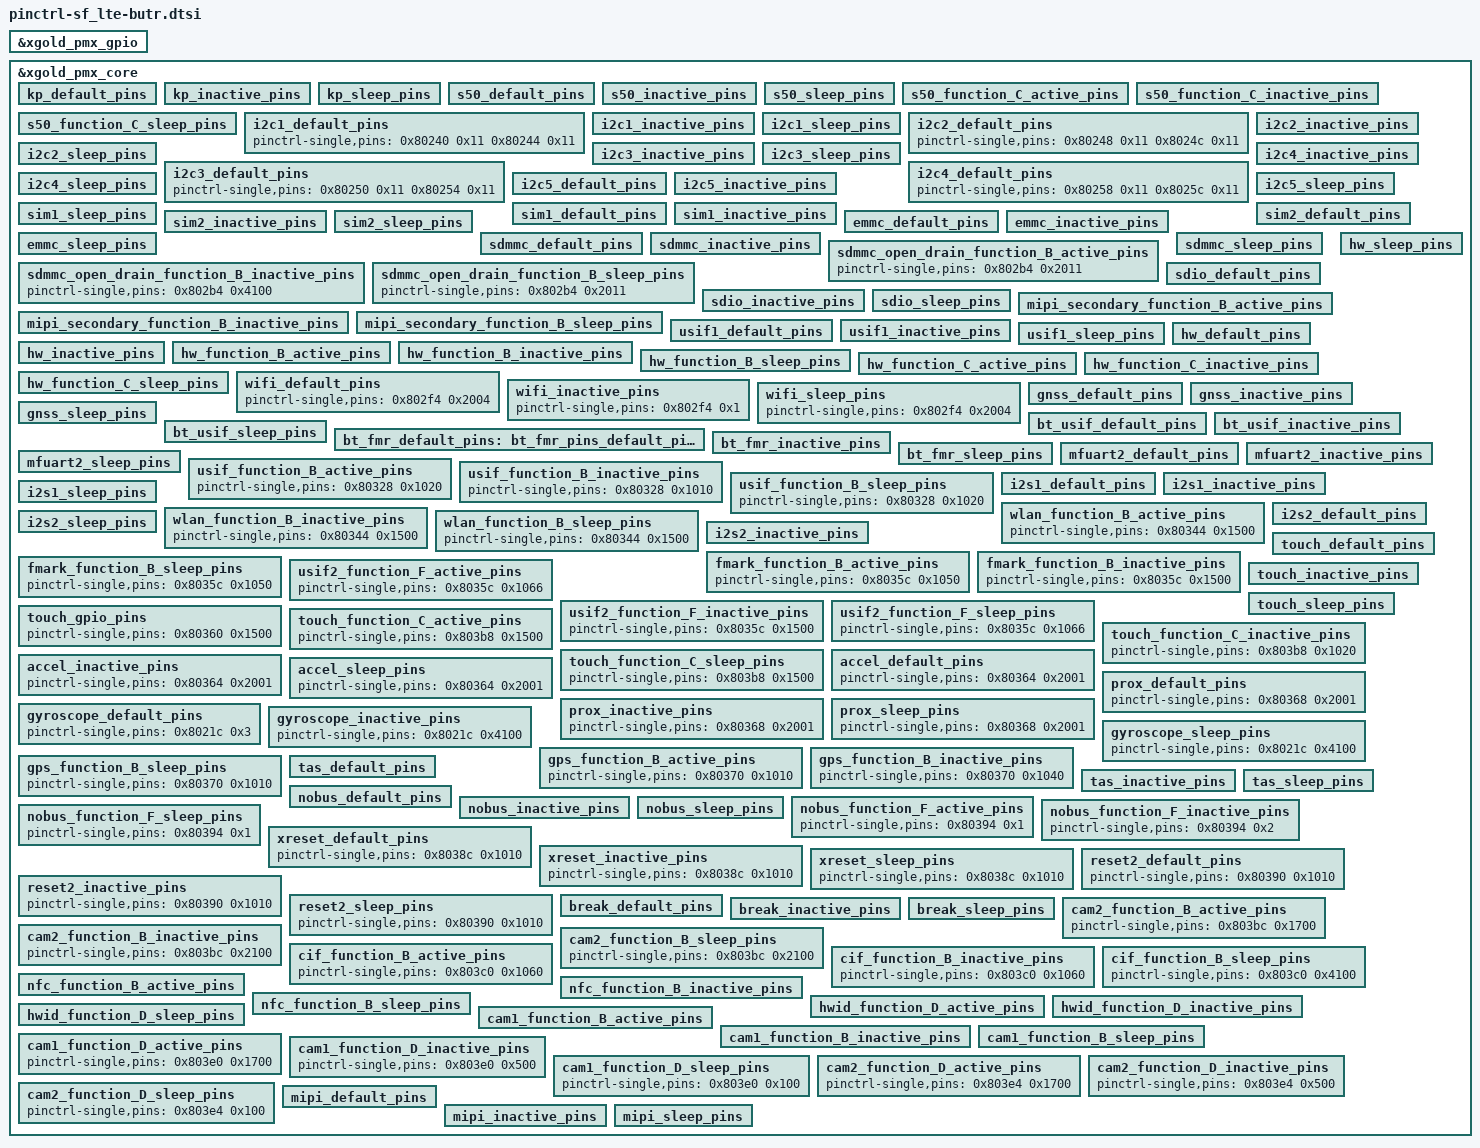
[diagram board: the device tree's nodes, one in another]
&xgold_pmx_gpio {
		intel,gpio-to-irq-num = < 16 >;
		intel,gpio-to-irq = <
			12 117  /* EXT_INT0 */
			67 118  /* EXT_INT1 */
			71 119  /* EXT_INT2 */
			14 120  /* EXT_INT3 */
			11 121  /* EXT_INT4 */
			27 122  /* EXT_INT5 */
			47 123  /* EXT_INT6 */
			45 124  /* EXT_INT7 */
			49 125  /* EXT_INT8 */
			70 126  /* EXT_INT9 */
			16 127  /* EXT_INT10 */
			17 128  /* EXT_INT11 */
			18 129  /* EXT_INT12 */
			19 130  /* EXT_INT13 */
			52 131  /* EXT_INT14 */
			56 132 >; /* EXT_INT15 */
};
&xgold_pmx_core {
	/* sparse GPIO range could be supported */
		/*first pin / nb pins / value */
	pinctrl-single,gpio-range =
		<&range 0 14 0x100>,
		<&range 15 1 0x1700>,   /* dif_reset */
		<&range 16 55 0x100>,
		<&range 71 1 0x1700>,   /* gnss_poweron */
		<&range 72 5 0x100>,
		<&range 77 1 0x1500>,   /* bt_fmr_enable*/
		<&range 78 10 0x100>,
		<&range 88 1 0x01700>,  /* touch_irq */
		<&range 89 21 0x100>,
		<&range 110 1 0x1500>,  /* touch_reset */
		<&range 111 1 0x01500>,	/* cam2_pd */
		<&range 112 6 0x100>,
		<&range 118 1 0x01500>,	/* cam1_pd */
		<&range 119 1 0x100>,
		<&range 120 1 0x01500>,	/* cam1_rst */
		<&range 121 1 0x01500>,	/* cam2_rst */
		<&range 122 20 0x100>;

	pinctrl-names = "default", "sleep", "deactivate"; /*"activate", "sleep", "deactivate" */
	/* map here static pins (do not need any dynamic config) */
	pinctrl-0 = <>;
	pinctrl-1 = <>;
	pinctrl-2 = <>;


	kp_default_pins:kp_default_pins {
		pinctrl-single,pins = <
			0x80200 0x2001	/* kp_in0 */
			0x80204 0x2001	/* kp_in1 */
			0x80220 0x10	/* kp_out0 */
			0x80228 0x10	/* kp_out2 */
		>;
	};
	kp_inactive_pins:kp_inactive_pins {
		pinctrl-single,pins = <
			0x80200 0x2001	/* kp_in0 */
			0x80204 0x2001	/* kp_in1 */
			0x80220 0x10	/* kp_out0 */
			0x80228 0x10	/* kp_out2 */
		>;
	};
	kp_sleep_pins:kp_sleep_pins {
		pinctrl-single,pins = <
			0x80200 0x2001	/* kp_in0 */
			0x80204 0x2001	/* kp_in1 */
			0x80220 0x10	/* kp_out0 */
			0x80228 0x10	/* kp_out2 */
		>;
	};
	s50_default_pins:s50_default_pins {
		pinctrl-single,pins = <
			0x803b4 0x1020	/* s50_tpiu_traceclk */
			0x803b8 0x1020	/* s50_tpiu_tracectl */
		>;
	};
	s50_inactive_pins:s50_inactive_pins {
		pinctrl-single,pins = <
			0x803b4 0x1020	/* s50_tpiu_traceclk */
			0x803b8 0x1020	/* s50_tpiu_tracectl */
		>;
	};
	s50_sleep_pins:s50_sleep_pins {
		pinctrl-single,pins = <
			0x803b4 0x1020	/* s50_tpiu_traceclk */
			0x803b8 0x1020	/* s50_tpiu_tracectl */
		>;
	};
	s50_function_C_active_pins:s50_function_C_active_pins {
		pinctrl-single,pins = <
			0x80200 0x1060	/* s50_tpiu_tracedata0 */
			0x80204 0x1060	/* s50_tpiu_tracedata1 */
			0x80220 0x1060	/* s50_tpiu_tracedata8 */
		>;
	};
	s50_function_C_inactive_pins:s50_function_C_inactive_pins {
		pinctrl-single,pins = <
			0x80200 0x2001	/* s50_tpiu_tracedata0 */
			0x80204 0x2001	/* s50_tpiu_tracedata1 */
			0x80220 0x10	/* s50_tpiu_tracedata8 */
		>;
	};
	s50_function_C_sleep_pins:s50_function_C_sleep_pins {
		pinctrl-single,pins = <
			0x80200 0x1060	/* s50_tpiu_tracedata0 */
			0x80204 0x1060	/* s50_tpiu_tracedata1 */
			0x80220 0x1060	/* s50_tpiu_tracedata8 */
		>;
	};
	i2c1_default_pins:i2c1_default_pins {
		pinctrl-single,pins = <
			0x80240 0x11	/* i2c1_scl */
			0x80244 0x11	/* i2c1_sda */
		>;
	};
	i2c1_inactive_pins:i2c1_inactive_pins {
		pinctrl-single,pins = <
			0x80240 0x2100	/* i2c1_scl */
			0x80244 0x2100	/* i2c1_sda */
		>;
	};
	i2c1_sleep_pins:i2c1_sleep_pins {
		pinctrl-single,pins = <
			0x80240 0x100	/* i2c1_scl */
			0x80244 0x100	/* i2c1_sda */
		>;
	};
	i2c2_default_pins:i2c2_default_pins {
		pinctrl-single,pins = <
			0x80248 0x11	/* i2c2_scl */
			0x8024c 0x11	/* i2c2_sda */
		>;
	};
	i2c2_inactive_pins:i2c2_inactive_pins {
		pinctrl-single,pins = <
			0x80248 0x2100	/* i2c2_scl */
			0x8024c 0x2100	/* i2c2_sda */
		>;
	};
	i2c2_sleep_pins:i2c2_sleep_pins {
		pinctrl-single,pins = <
			0x80248 0x100	/* i2c2_scl */
			0x8024c 0x100	/* i2c2_sda */
		>;
	};
	i2c3_default_pins:i2c3_default_pins {
		pinctrl-single,pins = <
			0x80250 0x11	/* i2c3_scl */
			0x80254 0x11	/* i2c3_sda */
		>;
	};
	i2c3_inactive_pins:i2c3_inactive_pins {
		pinctrl-single,pins = <
			0x80250 0x2100	/* i2c3_scl */
			0x80254 0x2100	/* i2c3_sda */
		>;
	};
	i2c3_sleep_pins:i2c3_sleep_pins {
		pinctrl-single,pins = <
			0x80250 0x100	/* i2c3_scl */
			0x80254 0x100	/* i2c3_sda */
		>;
	};
	i2c4_default_pins:i2c4_default_pins {
		pinctrl-single,pins = <
			0x80258 0x11	/* i2c4_scl */
			0x8025c 0x11	/* i2c4_sda */
		>;
	};
	i2c4_inactive_pins:i2c4_inactive_pins {
		pinctrl-single,pins = <
			0x80258 0x2100	/* i2c4_scl */
			0x8025c 0x2100	/* i2c4_sda */
		>;
	};
	i2c4_sleep_pins:i2c4_sleep_pins {
		pinctrl-single,pins = <
			0x80258 0x100	/* i2c4_scl */
			0x8025c 0x100	/* i2c4_sda */
		>;
	};
	i2c5_default_pins:i2c5_default_pins {
		pinctrl-single,pins = <
			0x80260 0x2011	/* i2c5_scl */
			0x80264 0x2011	/* i2c5_sda */
		>;
	};
	i2c5_inactive_pins:i2c5_inactive_pins {
		pinctrl-single,pins = <
			0x80260 0x2100	/* i2c5_scl */
			0x80264 0x2100	/* i2c5_sda */
		>;
	};
	i2c5_sleep_pins:i2c5_sleep_pins {
		pinctrl-single,pins = <
			0x80260 0x100	/* i2c5_scl */
			0x80264 0x100	/* i2c5_sda */
		>;
	};
	sim1_default_pins:sim1_default_pins {
		pinctrl-single,pins = <
			0x80268 0x11	/* sim1_io */
			0x8026c 0x1010	/* sim1_rst */
			0x80270 0x1010	/* sim1_clk */
			0x80274 0x1	/* sim1_sw */
		>;
	};
	sim1_inactive_pins:sim1_inactive_pins {
		pinctrl-single,pins = <
			0x80268 0x11	/* sim1_io */
			0x8026c 0x10	/* sim1_rst */
			0x80270 0x10	/* sim1_clk */
			0x80274 0x100	/* sim1_sw */
		>;
	};
	sim1_sleep_pins:sim1_sleep_pins {
		pinctrl-single,pins = <
			0x80268 0x11	/* sim1_io */
			0x8026c 0x1010	/* sim1_rst */
			0x80270 0x1010	/* sim1_clk */
			0x80274 0x1	/* sim1_sw */
		>;
	};
	sim2_default_pins:sim2_default_pins {
		pinctrl-single,pins = <
			0x80278 0x11	/* sim2_io */
			0x8027c 0x1010	/* sim2_clk */
			0x80280 0x1010	/* sim2_rst */
			0x80284 0x1	/* sim2_det */
		>;
	};
	sim2_inactive_pins:sim2_inactive_pins {
		pinctrl-single,pins = <
			0x80278 0x11	/* sim2_io */
			0x8027c 0x10	/* sim2_clk */
			0x80280 0x10	/* sim2_rst */
			0x80284 0x100	/* sim2_det */
		>;
	};
	sim2_sleep_pins:sim2_sleep_pins {
		pinctrl-single,pins = <
			0x80278 0x11	/* sim2_io */
			0x8027c 0x1010	/* sim2_clk */
			0x80280 0x1010	/* sim2_rst */
			0x80284 0x1	/* sim2_det */
		>;
	};
	emmc_default_pins:emmc_default_pins {
		pinctrl-single,pins = <
			0x80288 0x31011	/* emmc_clk */
			0x8028c 0x33011	/* emmc_cmd */
			0x80290 0x33011	/* emmc_dat0 */
			0x80294 0x33011	/* emmc_dat1 */
			0x80298 0x33011	/* emmc_dat2 */
			0x8029c 0x33011	/* emmc_dat3 */
			0x802a0 0x33011	/* emmc_dat4 */
			0x802a4 0x33011	/* emmc_dat5 */
			0x802a8 0x33011	/* emmc_dat6 */
			0x802ac 0x33011	/* emmc_dat7 */
			0x802b0 0x11010	/* emmc_reset */
		>;
	};
	emmc_inactive_pins:emmc_inactive_pins {
		pinctrl-single,pins = <
			0x80288 0x2100	/* emmc_clk */
			0x8028c 0x2100	/* emmc_cmd */
			0x80290 0x2100	/* emmc_dat0 */
			0x80294 0x2100	/* emmc_dat1 */
			0x80298 0x2100	/* emmc_dat2 */
			0x8029c 0x2100	/* emmc_dat3 */
			0x802a0 0x2100	/* emmc_dat4 */
			0x802a4 0x2100	/* emmc_dat5 */
			0x802a8 0x2100	/* emmc_dat6 */
			0x802ac 0x2100	/* emmc_dat7 */
			0x802b0 0x2100	/* emmc_reset */
		>;
	};
	emmc_sleep_pins:emmc_sleep_pins {
		pinctrl-single,pins = <
			0x80288 0x1010	/* emmc_clk */
			0x8028c 0x3011	/* emmc_cmd */
			0x80290 0x3011	/* emmc_dat0 */
			0x80294 0x3011	/* emmc_dat1 */
			0x80298 0x3011	/* emmc_dat2 */
			0x8029c 0x3011	/* emmc_dat3 */
			0x802a0 0x3011	/* emmc_dat4 */
			0x802a4 0x3011	/* emmc_dat5 */
			0x802a8 0x3011	/* emmc_dat6 */
			0x802ac 0x3011	/* emmc_dat7 */
			0x802b0 0x1010	/* emmc_reset */
		>;
	};
	sdmmc_default_pins:sdmmc_default_pins {
		pinctrl-single,pins = <
			0x802b4 0x3011	/* sdmmc_cmd */
			0x802b8 0x3011	/* sdmmc_clk */
			0x802bc 0x3011	/* sdmmc_dat0 */
			0x802c0 0x3011	/* sdmmc_dat1 */
			0x802c4 0x3011	/* sdmmc_dat2 */
			0x802c8 0x1011	/* sdmmc_dat3 */
			0x802cc 0x1100	/* sdmmc_card_detect */
		>;
	};
	sdmmc_inactive_pins:sdmmc_inactive_pins {
		pinctrl-single,pins = <
			0x802b4 0x4100	/* sdmmc_cmd */
			0x802b8 0x4100	/* sdmmc_clk */
			0x802bc 0x4100	/* sdmmc_dat0 */
			0x802c0 0x4100	/* sdmmc_dat1 */
			0x802c4 0x4100	/* sdmmc_dat2 */
			0x802c8 0x4100	/* sdmmc_dat3 */
			0x802cc 0x1	/* sdmmc_card_detect */
		>;
	};
	sdmmc_sleep_pins:sdmmc_sleep_pins {
		pinctrl-single,pins = <
			0x802b4 0x3011	/* sdmmc_cmd */
			0x802b8 0x3011	/* sdmmc_clk */
			0x802bc 0x3011	/* sdmmc_dat0 */
			0x802c0 0x3011	/* sdmmc_dat1 */
			0x802c4 0x3011	/* sdmmc_dat2 */
			0x802c8 0x1011	/* sdmmc_dat3 */
			0x802cc 0x1	/* sdmmc_card_detect */
		>;
	};
	sdmmc_open_drain_function_B_active_pins:sdmmc_open_drain_function_B_active_pins {
		pinctrl-single,pins = <
			0x802b4 0x2011	/* sdmmc_cmd_open_drain */
		>;
	};
	sdmmc_open_drain_function_B_inactive_pins:sdmmc_open_drain_function_B_inactive_pins {
		pinctrl-single,pins = <
			0x802b4 0x4100	/* sdmmc_cmd_open_drain */
		>;
	};
	sdmmc_open_drain_function_B_sleep_pins:sdmmc_open_drain_function_B_sleep_pins {
		pinctrl-single,pins = <
			0x802b4 0x2011	/* sdmmc_cmd_open_drain */
		>;
	};

	sdio_default_pins:sdio_default_pins {
		pinctrl-single,pins = <
			0x802d0 0x33011	/* sdio_cmd */
			0x802d4 0x33011	/* sdio_clk */
			0x802d8 0x33011	/* sdio_dat0 */
			0x802dc 0x33011	/* sdio_dat1 */
			0x802e0 0x33011	/* sdio_dat2 */
			0x802e4 0x33011	/* sdio_dat3 */
			0x802e8 0x2006  /* sdio_card_reset */
			0x80344 0x1700	/* i2s1_wa1 */
		>;
	};
	sdio_inactive_pins:sdio_inactive_pins {
		pinctrl-single,pins = <
			0x802d0 0x4100	/* sdio_cmd */
			0x802d4 0x4100	/* sdio_clk */
			0x802d8 0x4100	/* sdio_dat0 */
			0x802dc 0x4100	/* sdio_dat1 */
			0x802e0 0x4100	/* sdio_dat2 */
			0x802e4 0x4100	/* sdio_dat3 */
			0x802e8 0x2100	/* sdio_card_reset */
			0x80344 0x1500	/* i2s1_wa1 */
		>;
	};
	sdio_sleep_pins:sdio_sleep_pins {
		pinctrl-single,pins = <
			0x802d0 0x3011	/* sdio_cmd */
			0x802d4 0x3011	/* sdio_clk */
			0x802d8 0x3011	/* sdio_dat0 */
			0x802dc 0x3011	/* sdio_dat1 */
			0x802e0 0x3011	/* sdio_dat2 */
			0x802e4 0x3011	/* sdio_dat3 */
			0x802e8 0x2006	/* sdio_card_reset */
			0x80344 0x1500	/* i2s1_wa1 */
		>;
	};

	mipi_secondary_function_B_active_pins:mipi_secondary_function_B_active_pins {
		pinctrl-single,pins = <
			0x802b8 0x1030	/* mipi_trace_clk_secondary */
			0x802bc 0x1030	/* mipi_trace_data0_secondary */
			0x802c0 0x1030	/* mipi_trace_data1_secondary */
			0x802c4 0x1030	/* mipi_trace_data2_secondary */
			0x802c8 0x1030	/* mipi_trace_data3_secondary */
		>;
	};
	mipi_secondary_function_B_inactive_pins:mipi_secondary_function_B_inactive_pins {
		pinctrl-single,pins = <
			0x802b8 0x4100	/* mipi_trace_clk_secondary */
			0x802bc 0x4100	/* mipi_trace_data0_secondary */
			0x802c0 0x4100	/* mipi_trace_data1_secondary */
			0x802c4 0x4100	/* mipi_trace_data2_secondary */
			0x802c8 0x4100	/* mipi_trace_data3_secondary */
		>;
	};
	mipi_secondary_function_B_sleep_pins:mipi_secondary_function_B_sleep_pins {
		pinctrl-single,pins = <
			0x802b8 0x1030	/* mipi_trace_clk_secondary */
			0x802bc 0x1030	/* mipi_trace_data0_secondary */
			0x802c0 0x1030	/* mipi_trace_data1_secondary */
			0x802c4 0x1030	/* mipi_trace_data2_secondary */
			0x802c8 0x1030	/* mipi_trace_data3_secondary */
		>;
	};
	usif1_default_pins:usif1_default_pins {
		pinctrl-single,pins = <
			0x802ec 0x1010	/* usif1_txd_mtsr */
			0x802f0 0x2001	/* usif1_rxd_mrst */
			0x802f8 0x1010	/* usif1_rts_n */
			0x802fc 0x2001	/* usif1_cts_n */
		>;
	};
	usif1_inactive_pins:usif1_inactive_pins {
		pinctrl-single,pins = <
			0x802ec 0x1010	/* usif1_txd_mtsr */
			0x802f0 0x2001	/* usif1_rxd_mrst */
			0x802f8 0x1010	/* usif1_rts_n */
			0x802fc 0x2001	/* usif1_cts_n */
		>;
	};
	usif1_sleep_pins:usif1_sleep_pins {
		pinctrl-single,pins = <
			0x802ec 0x1010	/* usif1_txd_mtsr */
			0x802f0 0x2001	/* usif1_rxd_mrst */
			0x802f8 0x1010	/* usif1_rts_n */
			0x802fc 0x2001	/* usif1_cts_n */
		>;
	};
	hw_default_pins:hw_default_pins {
		pinctrl-single,pins = <
			0x803bc 0x1010	/* hw_mon18 */
			0x803c0 0x1010	/* hw_mon19 */
			0x803d0 0x1010	/* hw_mon23 */
			0x803d4 0x1010	/* hw_mon24 */
			0x803d8 0x1010	/* hw_mon25 */
			0x803e0 0x1010	/* hw_mon27 */
			0x803e4 0x1010	/* hw_mon28 */
			0x803e8 0x1010	/* hw_mon29 */
		>;
	};
	hw_inactive_pins:hw_inactive_pins {
		pinctrl-single,pins = <
			0x803bc 0x1500	/* hw_mon18 */
			0x803c0 0x1060	/* hw_mon19 */
			0x803d0 0x1500	/* hw_mon23 */
			0x803d4 0x1500	/* hw_mon24 */
			0x803d8 0x1700	/* hw_mon25 */
			0x803e0 0x500	/* hw_mon27 */
			0x803e4 0x500	/* hw_mon28 */
			0x803e8 0x1500	/* hw_mon29 */
		>;
	};
	hw_sleep_pins:hw_sleep_pins {
		pinctrl-single,pins = <
			0x803bc 0x1010	/* hw_mon18 */
			0x803c0 0x1010	/* hw_mon19 */
			0x803d0 0x1010	/* hw_mon23 */
			0x803d4 0x1010	/* hw_mon24 */
			0x803d8 0x1410	/* hw_mon25 */
			0x803e0 0x1410	/* hw_mon27 */
			0x803e4 0x1410	/* hw_mon28 */
			0x803e8 0x1410	/* hw_mon29 */
		>;
	};
	hw_function_B_active_pins:hw_function_B_active_pins {
		pinctrl-single,pins = <
			0x802ec 0x1020	/* hw_mon12 */
			0x802f0 0x1020	/* hw_mon13 */
			0x802f4 0x1020	/* hw_mon14 */
			0x802f8 0x1020	/* hw_mon15 */
			0x80310 0x1020	/* hw_mon3 */
			0x80314 0x1020	/* hw_mon4 */
			0x80320 0x1020	/* hw_mon5 */
			0x80324 0x1020	/* hw_mon6 */
			0x803b4 0x1010	/* hw_mon16 */
			0x803b8 0x1010	/* hw_mon17 */
			0x803f8 0x1030	/* hw_mon8 */
			0x803fc 0x1030	/* hw_mon9 */
			0x80400 0x1030	/* hw_mon10 */
			0x80404 0x1030	/* hw_mon11 */
			0x80418 0x1030	/* hw_mon7 */
		>;
	};
	hw_function_B_inactive_pins:hw_function_B_inactive_pins {
		pinctrl-single,pins = <
			0x802ec 0x1010	/* hw_mon12 */
			0x802f0 0x2001	/* hw_mon13 */
			0x802f4 0x1	/* hw_mon14 */
			0x802f8 0x1010	/* hw_mon15 */
			0x80310 0x1010	/* hw_mon3 */
			0x80314 0x2001	/* hw_mon4 */
			0x80320 0x1010	/* hw_mon5 */
			0x80324 0x2001	/* hw_mon6 */
			0x803b4 0x1020	/* hw_mon16 */
			0x803b8 0x1020	/* hw_mon17 */
			0x803f8 0x1010	/* hw_mon8 */
			0x803fc 0x1010	/* hw_mon9 */
			0x80400 0x1010	/* hw_mon10 */
			0x80404 0x1010	/* hw_mon11 */
			0x80418 0x1010	/* hw_mon7 */
		>;
	};
	hw_function_B_sleep_pins:hw_function_B_sleep_pins {
		pinctrl-single,pins = <
			0x802ec 0x1020	/* hw_mon12 */
			0x802f0 0x1020	/* hw_mon13 */
			0x802f4 0x1020	/* hw_mon14 */
			0x802f8 0x1020	/* hw_mon15 */
			0x80310 0x1020	/* hw_mon3 */
			0x80314 0x1020	/* hw_mon4 */
			0x80320 0x1020	/* hw_mon5 */
			0x80324 0x1020	/* hw_mon6 */
			0x803b4 0x1010	/* hw_mon16 */
			0x803b8 0x1010	/* hw_mon17 */
			0x803f8 0x1030	/* hw_mon8 */
			0x803fc 0x1030	/* hw_mon9 */
			0x80400 0x1030	/* hw_mon10 */
			0x80404 0x1030	/* hw_mon11 */
			0x80418 0x1030	/* hw_mon7 */
		>;
	};
	hw_function_C_active_pins:hw_function_C_active_pins {
		pinctrl-single,pins = <
			0x803ac 0x1010	/* hw_mon2 */
			0x803b0 0x1010	/* hw_mon2 */
		>;
	};
	hw_function_C_inactive_pins:hw_function_C_inactive_pins {
		pinctrl-single,pins = <
			0x803ac 0x1020	/* hw_mon2 */
			0x803b0 0x1500	/* hw_mon2 */
		>;
	};
	hw_function_C_sleep_pins:hw_function_C_sleep_pins {
		pinctrl-single,pins = <
			0x803ac 0x1010	/* hw_mon2 */
			0x803b0 0x1010	/* hw_mon2 */
		>;
	};
	wifi_default_pins:wifi_default_pins {
		pinctrl-single,pins = <
			0x802f4 0x2004	/* wifi_audio_irq */
		>;
	};
	wifi_inactive_pins:wifi_inactive_pins {
		pinctrl-single,pins = <
			0x802f4 0x1	/* wifi_audio_irq */
		>;
	};
	wifi_sleep_pins:wifi_sleep_pins {
		pinctrl-single,pins = <
			0x802f4 0x2004	/* wifi_audio_irq */
		>;
	};
	gnss_default_pins:gnss_default_pins {
		pinctrl-single,pins = <
			0x80300 0x1010	/* gnss_uart_txd */
			0x80304 0x2001	/* gnss_uart_rxd */
			0x80308 0x1010	/* gnss_uart_rts */
			0x8030c 0x2001	/* gnss_uart_cts */
			0x8031c 0x1500	/* gnss_poweron */
			0x8036c 0x1020	/* gnss_ext_frm_sync */
			0x80370 0x1040	/* gnss_ext_duty_cycle */
		>;
	};
	gnss_inactive_pins:gnss_inactive_pins {
		pinctrl-single,pins = <
			0x80300 0x1010	/* gnss_uart_txd */
			0x80304 0x2001	/* gnss_uart_rxd */
			0x80308 0x1010	/* gnss_uart_rts */
			0x8030c 0x2001	/* gnss_uart_cts */
			0x8036c 0x1020	/* gnss_ext_frm_sync */
			0x80370 0x1040	/* gnss_ext_duty_cycle */
		>;
	};
	gnss_sleep_pins:gnss_sleep_pins {
		pinctrl-single,pins = <
			0x80300 0x1010	/* gnss_uart_txd */
			0x80304 0x2001	/* gnss_uart_rxd */
			0x80308 0x1010	/* gnss_uart_rts */
			0x8030c 0x2001	/* gnss_uart_cts */
			0x8036c 0x1020	/* gnss_ext_frm_sync */
			0x80370 0x1040	/* gnss_ext_duty_cycle */
		>;
	};

	bt_usif_default_pins:bt_usif_default_pins {
		pinctrl-single,pins = <
			0x80310 0x1010	/* bt_uart_txd */
			0x80314 0x2001	/* bt_uart_rxd */
			0x80320 0x1010	/* bt_uart_rts */
			0x80324 0x2001	/* bt_uart_cts */
		>;
	};
	bt_usif_inactive_pins:bt_usif_inactive_pins {
		pinctrl-single,pins = <
			0x80310 0x1010	/* bt_uart_txd */
			0x80314 0x2001	/* bt_uart_rxd */
			0x80320 0x1010	/* bt_uart_rts */
			0x80324 0x2001	/* bt_uart_cts */
		>;
	};
	bt_usif_sleep_pins:bt_usif_sleep_pins {
		pinctrl-single,pins = <
			0x80310 0x1010	/* bt_uart_txd */
			0x80314 0x2001	/* bt_uart_rxd */
			0x80320 0x1010	/* bt_uart_rts */
			0x80324 0x2001	/* bt_uart_cts */
		>;
	};

	bt_fmr_default_pins:bt_fmr_pins_default_pins {
		pinctrl-single,pins = <
			0x80334 0x1500	/* bt_fm_en */
			0x80318 0x2003	/* bt_wakeup_host */
		>;
	};

	bt_fmr_inactive_pins:bt_fmr_inactive_pins {
		pinctrl-single,pins = <
			0x80334 0x1500	/* bt_fm_en */
			0x80318 0x1010	/* bt_wakeup_host */
		>;
	};

	bt_fmr_sleep_pins:bt_fmr_sleep_pins {
		pinctrl-single,pins = <
			0x80334 0x1500	/* bt_fm_en */
			0x80318 0x2003	/* bt_wakeup_host */
		>;
	};

	mfuart2_default_pins:mfuart2_default_pins {
		pinctrl-single,pins = <
			0x80328 0x1010	/* mfuart2_txd */
			0x8032c 0x2001	/* mfuart2_rxd */
		>;
	};
	mfuart2_inactive_pins:mfuart2_inactive_pins {
		pinctrl-single,pins = <
			0x80328 0x1010	/* mfuart2_txd */
			0x8032c 0x2001	/* mfuart2_rxd */
		>;
	};
	mfuart2_sleep_pins:mfuart2_sleep_pins {
		pinctrl-single,pins = <
			0x80328 0x1010	/* mfuart2_txd */
			0x8032c 0x2001	/* mfuart2_rxd */
		>;
	};
	usif_function_B_active_pins:usif_function_B_active_pins {
		pinctrl-single,pins = <
			0x80328 0x1020	/* usif_lte_txd */
		>;
	};
	usif_function_B_inactive_pins:usif_function_B_inactive_pins {
		pinctrl-single,pins = <
			0x80328 0x1010	/* usif_lte_txd */
		>;
	};
	usif_function_B_sleep_pins:usif_function_B_sleep_pins {
		pinctrl-single,pins = <
			0x80328 0x1020	/* usif_lte_txd */
		>;
	};
	i2s1_default_pins:i2s1_default_pins {
		pinctrl-single,pins = <
			0x80330 0x1010	/* i2s1_clk0 */
			0x80338 0x4001	/* i2s1_rx */
			0x8033c 0x1010	/* i2s1_tx */
			0x80340 0x1010	/* i2s1_wa0 */
		>;
	};
	i2s1_inactive_pins:i2s1_inactive_pins {
		pinctrl-single,pins = <
			0x80330 0x1500	/* i2s1_clk0 */
			0x80338 0x2100	/* i2s1_rx */
			0x8033c 0x1500	/* i2s1_tx */
			0x80340 0x1500	/* i2s1_wa0 */
		>;
	};
	i2s1_sleep_pins:i2s1_sleep_pins {
		pinctrl-single,pins = <
			0x80330 0x1500	/* i2s1_clk0 */
			0x80338 0x4100	/* i2s1_rx */
			0x8033c 0x1500	/* i2s1_tx */
			0x80340 0x1500	/* i2s1_wa0 */
		>;
	};
	wlan_function_B_active_pins:wlan_function_B_active_pins {
		pinctrl-single,pins = <
			0x80344 0x1500	/* wlan_en */
		>;
	};
	wlan_function_B_inactive_pins:wlan_function_B_inactive_pins {
		pinctrl-single,pins = <
			0x80344 0x1500	/* wlan_en */
		>;
	};
	wlan_function_B_sleep_pins:wlan_function_B_sleep_pins {
		pinctrl-single,pins = <
			0x80344 0x1500	/* wlan_en */
		>;
	};
	i2s2_default_pins:i2s2_default_pins {
		pinctrl-single,pins = <
			0x80348 0x1010	/* i2s2_clk0 */
			0x8034c 0x1010	/* i2s2_clk1 */
			0x80350 0x1	/* i2s2_rx */
			0x80354 0x1010	/* i2s2_tx */
			0x80358 0x1010	/* i2s2_wa0 */
			0x8035c 0x1010	/* i2s2_wa1 */
		>;
	};
	i2s2_inactive_pins:i2s2_inactive_pins {
		pinctrl-single,pins = <
			0x80348 0x1500	/* i2s2_clk0 */
			0x8034c 0x1500	/* i2s2_clk1 */
			0x80350 0x2100	/* i2s2_rx */
			0x80354 0x1500	/* i2s2_tx */
			0x80358 0x1500	/* i2s2_wa0 */
			0x8035c 0x1500	/* i2s2_wa1 */
		>;
	};
	i2s2_sleep_pins:i2s2_sleep_pins {
		pinctrl-single,pins = <
			0x80348 0x1500	/* i2s2_clk0 */
			0x8034c 0x1500	/* i2s2_clk1 */
			0x80350 0x4100	/* i2s2_rx */
			0x80354 0x1500	/* i2s2_tx */
			0x80358 0x1500	/* i2s2_wa0 */
			0x8035c 0x1500	/* i2s2_wa1 */
		>;
	};
	fmark_function_B_active_pins:fmark_function_B_active_pins {
		pinctrl-single,pins = <
			0x8035c 0x1050	/* fmark_i2s2_wa1 */
		>;
	};
	fmark_function_B_inactive_pins:fmark_function_B_inactive_pins {
		pinctrl-single,pins = <
			0x8035c 0x1500	/* fmark_i2s2_wa1 */
		>;
	};
	fmark_function_B_sleep_pins:fmark_function_B_sleep_pins {
		pinctrl-single,pins = <
			0x8035c 0x1050	/* fmark_i2s2_wa1 */
		>;
	};
	usif2_function_F_active_pins:usif2_function_F_active_pins {
		pinctrl-single,pins = <
			0x8035c 0x1066	/* usif2_sclk */
		>;
	};
	usif2_function_F_inactive_pins:usif2_function_F_inactive_pins {
		pinctrl-single,pins = <
			0x8035c 0x1500	/* usif2_sclk */
		>;
	};
	usif2_function_F_sleep_pins:usif2_function_F_sleep_pins {
		pinctrl-single,pins = <
			0x8035c 0x1066	/* usif2_sclk */
		>;
	};
	touch_default_pins:touch_default_pins {
		pinctrl-single,pins = <
			0x803b8 0x1700	/* touch_reset_n */
			0x80360 0x2001	/* touch_irq_n */
		>;
	};
	touch_inactive_pins:touch_inactive_pins {
		pinctrl-single,pins = <
			0x803b8 0x1500	/* touch_reset_n */
			0x80360 0x2001	/* touch_irq_n */
		>;
	};
	touch_sleep_pins:touch_sleep_pins {
		pinctrl-single,pins = <
			0x803b8 0x1500	/* touch_reset_n */
			0x80360 0x2001	/* touch_irq_n */
		>;
	};
	touch_gpio_pins:touch_gpio_pins {
		pinctrl-single,pins = <
			0x80360 0x1500 /* touch_irq_n */
		>;
	};
	touch_function_C_active_pins:touch_function_C_active_pins {
		pinctrl-single,pins = <
			0x803b8 0x1500	/* touch_reset_n */
		>;
	};
	touch_function_C_inactive_pins:touch_function_C_inactive_pins {
		pinctrl-single,pins = <
			0x803b8 0x1020	/* touch_reset_n */
		>;
	};
	touch_function_C_sleep_pins:touch_function_C_sleep_pins {
		pinctrl-single,pins = <
			0x803b8 0x1500	/* touch_reset_n */
		>;
	};
	accel_default_pins:accel_default_pins {
		pinctrl-single,pins = <
			0x80364 0x2001	/* accel_mag_irq */
		>;
	};
	accel_inactive_pins:accel_inactive_pins {
		pinctrl-single,pins = <
			0x80364 0x2001	/* accel_mag_irq */
		>;
	};
	accel_sleep_pins:accel_sleep_pins {
		pinctrl-single,pins = <
			0x80364 0x2001	/* accel_mag_irq */
		>;
	};
	prox_default_pins:prox_default_pins {
		pinctrl-single,pins = <
			0x80368 0x2001	/* prox_amb_irq */
		>;
	};
	prox_inactive_pins:prox_inactive_pins {
		pinctrl-single,pins = <
			0x80368 0x2001	/* prox_amb_irq */
		>;
	};
	prox_sleep_pins:prox_sleep_pins {
		pinctrl-single,pins = <
			0x80368 0x2001	/* prox_amb_irq */
		>;
	};
	gyroscope_default_pins:gyroscope_default_pins {
		pinctrl-single,pins = <
			0x8021c 0x3	/* gyroscope_irq */
		>;
	};
	gyroscope_inactive_pins:gyroscope_inactive_pins {
		pinctrl-single,pins = <
			0x8021c 0x4100	/* gyroscope_irq */
		>;
	};
	gyroscope_sleep_pins:gyroscope_sleep_pins {
		pinctrl-single,pins = <
			0x8021c 0x4100	/* gyroscope_irq */
		>;
	};
	gps_function_B_active_pins:gps_function_B_active_pins {
		pinctrl-single,pins = <
			0x80370 0x1010	/* gps_fta */
		>;
	};
	gps_function_B_inactive_pins:gps_function_B_inactive_pins {
		pinctrl-single,pins = <
			0x80370 0x1040	/* gps_fta */
		>;
	};
	gps_function_B_sleep_pins:gps_function_B_sleep_pins {
		pinctrl-single,pins = <
			0x80370 0x1010	/* gps_fta */
		>;
	};
	tas_default_pins:tas_default_pins {
		pinctrl-single,pins = <
			0x80374 0x1020	/* tas_tx1 */
			0x80378 0x1020	/* tas_rx1 */
		>;
	};
	tas_inactive_pins:tas_inactive_pins {
		pinctrl-single,pins = <
			0x80374 0x1020	/* tas_tx1 */
			0x80378 0x1020	/* tas_rx1 */
		>;
	};
	tas_sleep_pins:tas_sleep_pins {
		pinctrl-single,pins = <
			0x80374 0x1020	/* tas_tx1 */
			0x80378 0x1020	/* tas_rx1 */
		>;
	};
	nobus_default_pins:nobus_default_pins {
		pinctrl-single,pins = <
			0x80380 0x1010	/* clkout0 */
			0x80384 0x1010	/* clkout1 */
			0x80388 0x1010	/* clkout2 */
			0x803b0 0x1010	/* hwmon2 */
			0x8043c 0x1010	/* digrf1en */
			0x80440 0x1010	/* digrf2en */
		>;
	};
	nobus_inactive_pins:nobus_inactive_pins {
		pinctrl-single,pins = <
			0x80380 0x1010	/* clkout0 */
			0x80384 0x1010	/* clkout1 */
			0x80388 0x1010	/* clkout2 */
			0x803b0 0x1500	/* hwmon2 */
			0x8043c 0x1010	/* digrf1en */
			0x80440 0x1010	/* digrf2en */
		>;
	};
	nobus_sleep_pins:nobus_sleep_pins {
		pinctrl-single,pins = <
			0x80380 0x4100	/* clkout0 */
			0x80384 0x4100	/* clkout1 */
			0x80388 0x4100	/* clkout2 */
			0x803b0 0x1010	/* hwmon2 */
			0x8043c 0x1010	/* digrf1en */
			0x80440 0x1010	/* digrf2en */
		>;
	};
	nobus_function_F_active_pins:nobus_function_F_active_pins {
		pinctrl-single,pins = <
			0x80394 0x1	/* eint0 */
		>;
	};
	nobus_function_F_inactive_pins:nobus_function_F_inactive_pins {
		pinctrl-single,pins = <
			0x80394 0x2	/* eint0 */
		>;
	};
	nobus_function_F_sleep_pins:nobus_function_F_sleep_pins {
		pinctrl-single,pins = <
			0x80394 0x1	/* eint0 */
		>;
	};
	xreset_default_pins:xreset_default_pins {
		pinctrl-single,pins = <
			0x8038c 0x1010	/* xreset_n */
		>;
	};
	xreset_inactive_pins:xreset_inactive_pins {
		pinctrl-single,pins = <
			0x8038c 0x1010	/* xreset_n */
		>;
	};
	xreset_sleep_pins:xreset_sleep_pins {
		pinctrl-single,pins = <
			0x8038c 0x1010	/* xreset_n */
		>;
	};
	reset2_default_pins:reset2_default_pins {
		pinctrl-single,pins = <
			0x80390 0x1010	/* reset2_n */
		>;
	};
	reset2_inactive_pins:reset2_inactive_pins {
		pinctrl-single,pins = <
			0x80390 0x1010	/* reset2_n */
		>;
	};
	reset2_sleep_pins:reset2_sleep_pins {
		pinctrl-single,pins = <
			0x80390 0x1010	/* reset2_n */
		>;
	};
	break_default_pins:break_default_pins {
		pinctrl-single,pins = <
			0x803a8 0x1	/* break_in */
			0x803ac 0x1020	/* break_out */
		>;
	};
	break_inactive_pins:break_inactive_pins {
		pinctrl-single,pins = <
			0x803a8 0x1	/* break_in */
			0x803ac 0x1020	/* break_out */
		>;
	};
	break_sleep_pins:break_sleep_pins {
		pinctrl-single,pins = <
			0x803a8 0x1	/* break_in */
			0x803ac 0x1020	/* break_out */
		>;
	};

	s50_default_pins:s50_default_pins {
		pinctrl-single,pins = <
			0x803b4 0x1020	/* s50_tpiu_traceclk */
			0x803b8 0x1020	/* s50_tpiu_tracectl */
		>;
	};
	s50_inactive_pins:s50_inactive_pins {
		pinctrl-single,pins = <
			0x803b4 0x1020	/* s50_tpiu_traceclk */
			0x803b8 0x1020	/* s50_tpiu_tracectl */
		>;
	};
	s50_sleep_pins:s50_sleep_pins {
		pinctrl-single,pins = <
			0x803b4 0x1020	/* s50_tpiu_traceclk */
			0x803b8 0x1020	/* s50_tpiu_tracectl */
		>;
	};
	cam2_function_B_active_pins:cam2_function_B_active_pins {
		pinctrl-single,pins = <
			0x803bc 0x1700	/* cam2_pwd */
		>;
	};
	cam2_function_B_inactive_pins:cam2_function_B_inactive_pins {
		pinctrl-single,pins = <
			0x803bc 0x2100	/* cam2_pwd */
		>;
	};
	cam2_function_B_sleep_pins:cam2_function_B_sleep_pins {
		pinctrl-single,pins = <
			0x803bc 0x2100	/* cam2_pwd */
		>;
	};
	cif_function_B_active_pins:cif_function_B_active_pins {
		pinctrl-single,pins = <
			0x803c0 0x1060	/* cif_fl_trig_out */
		>;
	};
	cif_function_B_inactive_pins:cif_function_B_inactive_pins {
		pinctrl-single,pins = <
			0x803c0 0x1060	/* cif_fl_trig_out */
		>;
	};
	cif_function_B_sleep_pins:cif_function_B_sleep_pins {
		pinctrl-single,pins = <
			0x803c0 0x4100	/* cif_fl_trig_out */
		>;
	};
	nfc_function_B_active_pins:nfc_function_B_active_pins {
		pinctrl-single,pins = <
			0x803d0 0x1500	/* nfc_enable */
			0x803d4 0x1500	/* nfc_reset */
		>;
	};
	nfc_function_B_inactive_pins:nfc_function_B_inactive_pins {
		pinctrl-single,pins = <
			0x803d0 0x1500	/* nfc_enable */
			0x803d4 0x1500	/* nfc_reset */
		>;
	};
	nfc_function_B_sleep_pins:nfc_function_B_sleep_pins {
		pinctrl-single,pins = <
			0x803d0 0x1500	/* nfc_enable */
			0x803d4 0x1500	/* nfc_reset */
		>;
	};
	hwid_function_D_active_pins:hwid_function_D_active_pins {
		pinctrl-single,pins = <
			0x803d0 0x100	/* hwid_2 */
			0x803d4 0x100	/* hwid_3 */
		>;
	};
	hwid_function_D_inactive_pins:hwid_function_D_inactive_pins {
		pinctrl-single,pins = <
			0x803d0 0x1500	/* hwid_2 */
			0x803d4 0x1500	/* hwid_3 */
		>;
	};
	hwid_function_D_sleep_pins:hwid_function_D_sleep_pins {
		pinctrl-single,pins = <
			0x803d0 0x100	/* hwid_2 */
			0x803d4 0x100	/* hwid_3 */
		>;
	};
cam1_function_B_active_pins:cam1_function_B_active_pins {
	pinctrl-single,pins = <
		0x803d8 0x1500	/* cam1_pd */
		0x80380 0x1010    /* cam1_mclk*/
	>;
};
cam1_function_B_inactive_pins:cam1_function_B_inactive_pins {
	pinctrl-single,pins = <
		0x803d8 0x1700	/* cam1_pd */
		0x80380 0x1010 /*0x4100    /* cam1_mclk*/
	>;
};
cam1_function_B_sleep_pins:cam1_function_B_sleep_pins {
	pinctrl-single,pins = <
		0x803d8 0x2100	/* cam1_pd */
		0x80380 0x1010    /* cam1_mclk*/
	>;
};
cam1_function_D_active_pins:cam1_function_D_active_pins {
	pinctrl-single,pins = <
		0x803e0 0x1700	/* cam1_rst */
	>;
};
cam1_function_D_inactive_pins:cam1_function_D_inactive_pins {
	pinctrl-single,pins = <
		0x803e0 0x500	/* cam1_rst */
	>;
};
cam1_function_D_sleep_pins:cam1_function_D_sleep_pins {
	pinctrl-single,pins = <
		0x803e0 0x100	/* cam1_rst */
	>;
};
cam2_function_D_active_pins:cam2_function_D_active_pins {
	pinctrl-single,pins = <
		0x803e4 0x1700	/* cam2_rst */
	>;
};
cam2_function_D_inactive_pins:cam2_function_D_inactive_pins {
	pinctrl-single,pins = <
		0x803e4 0x500	/* cam2_rst */
	>;
};
cam2_function_D_sleep_pins:cam2_function_D_sleep_pins {
	pinctrl-single,pins = <
		0x803e4 0x100	/* cam2_rst */
	>;
};
	mipi_default_pins:mipi_default_pins {
		pinctrl-single,pins = <
			0x803f8 0x1010	/* mipi_trace_clk */
			0x803fc 0x1010	/* mipi_trace_data0 */
			0x80400 0x1010	/* mipi_trace_data1 */
			0x80404 0x1010	/* mipi_trace_data2 */
			0x80408 0x1010	/* mipi_trace_data3 */
			0x8040c 0x1010	/* mipi_trace_data4 */
			0x80410 0x1010	/* mipi_trace_data5 */
			0x80414 0x1010	/* mipi_trace_data6 */
			0x80418 0x1010	/* mipi_trace_data7 */
			0x8041c 0x1010	/* mipi_trace_data8 */
			0x80420 0x1010	/* mipi_trace_data9 */
			0x80424 0x1010	/* mipi_trace_data10 */
			0x80428 0x1010	/* mipi_trace_data11 */
			0x8042c 0x1010	/* mipi_trace_data12 */
			0x80430 0x1010	/* mipi_trace_data13 */
			0x80434 0x1010	/* mipi_trace_data14 */
			0x80438 0x1010	/* mipi_trace_data15 */
		>;
	};
	mipi_inactive_pins:mipi_inactive_pins {
		pinctrl-single,pins = <
			0x803f8 0x1010	/* mipi_trace_clk */
			0x803fc 0x1010	/* mipi_trace_data0 */
			0x80400 0x1010	/* mipi_trace_data1 */
			0x80404 0x1010	/* mipi_trace_data2 */
			0x80408 0x1010	/* mipi_trace_data3 */
			0x8040c 0x1010	/* mipi_trace_data4 */
			0x80410 0x1010	/* mipi_trace_data5 */
			0x80414 0x1010	/* mipi_trace_data6 */
			0x80418 0x1010	/* mipi_trace_data7 */
			0x8041c 0x1010	/* mipi_trace_data8 */
			0x80420 0x1010	/* mipi_trace_data9 */
			0x80424 0x1010	/* mipi_trace_data10 */
			0x80428 0x1010	/* mipi_trace_data11 */
			0x8042c 0x1010	/* mipi_trace_data12 */
			0x80430 0x1010	/* mipi_trace_data13 */
			0x80434 0x1010	/* mipi_trace_data14 */
			0x80438 0x1010	/* mipi_trace_data15 */
		>;
	};
	mipi_sleep_pins:mipi_sleep_pins {
		pinctrl-single,pins = <
			0x803f8 0x1010	/* mipi_trace_clk */
			0x803fc 0x1010	/* mipi_trace_data0 */
			0x80400 0x1010	/* mipi_trace_data1 */
			0x80404 0x1010	/* mipi_trace_data2 */
			0x80408 0x1010	/* mipi_trace_data3 */
			0x8040c 0x1010	/* mipi_trace_data4 */
			0x80410 0x1010	/* mipi_trace_data5 */
			0x80414 0x1010	/* mipi_trace_data6 */
			0x80418 0x1010	/* mipi_trace_data7 */
			0x8041c 0x1010	/* mipi_trace_data8 */
			0x80420 0x1010	/* mipi_trace_data9 */
			0x80424 0x1010	/* mipi_trace_data10 */
			0x80428 0x1010	/* mipi_trace_data11 */
			0x8042c 0x1010	/* mipi_trace_data12 */
			0x80430 0x1010	/* mipi_trace_data13 */
			0x80434 0x1010	/* mipi_trace_data14 */
			0x80438 0x1010	/* mipi_trace_data15 */
		>;
	};
};
